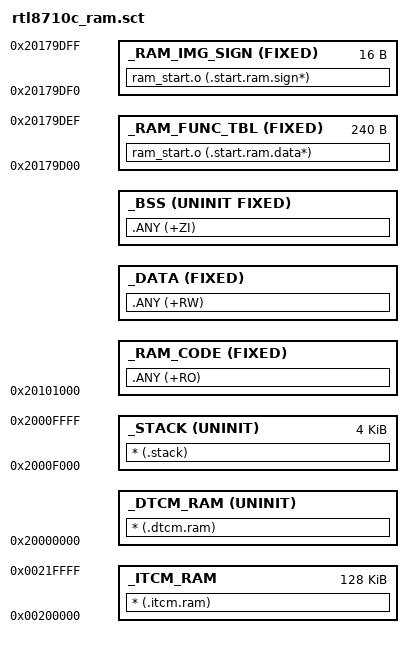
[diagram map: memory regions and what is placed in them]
; *************************************************************
; *** Scatter-Loading Description File for RTL8195BHP       ***
; *************************************************************
LR_ITCM 0x00000000 0x001FF000  {    ; load region size_region
  _ITCM_RAM 0x00200000 0x00020000  {  ; ITCM for Text & RO Data
  	* (.itcm.ram)
  }
}

LR_DTCM 0x20000000 0x00018000  {    ; load region size_region
  _DTCM_RAM 0x20000000 UNINIT {
  	* (.dtcm.ram)
  }
  
  _STACK 0x2000F000 UNINIT 0x00001000  {
  	* (.stack)
  }
}

LR_RAM 0x20100000 0x0017A000  {    ; load region size_region
  _RAM_CODE 0x20101000 FIXED {
    .ANY (+RO)
  }
  
  _DATA +0 FIXED {
    .ANY (+RW)
  }

  _BSS +0 UNINIT FIXED {
    .ANY (+ZI)
  }

  _RAM_FUNC_TBL 0x20179D00 FIXED 0xF0 {
    ram_start.o (.start.ram.data*)
  }

  _RAM_IMG_SIGN 0x20179DF0 FIXED 0x10  {
    ram_start.o (.start.ram.sign*)
  }
}
